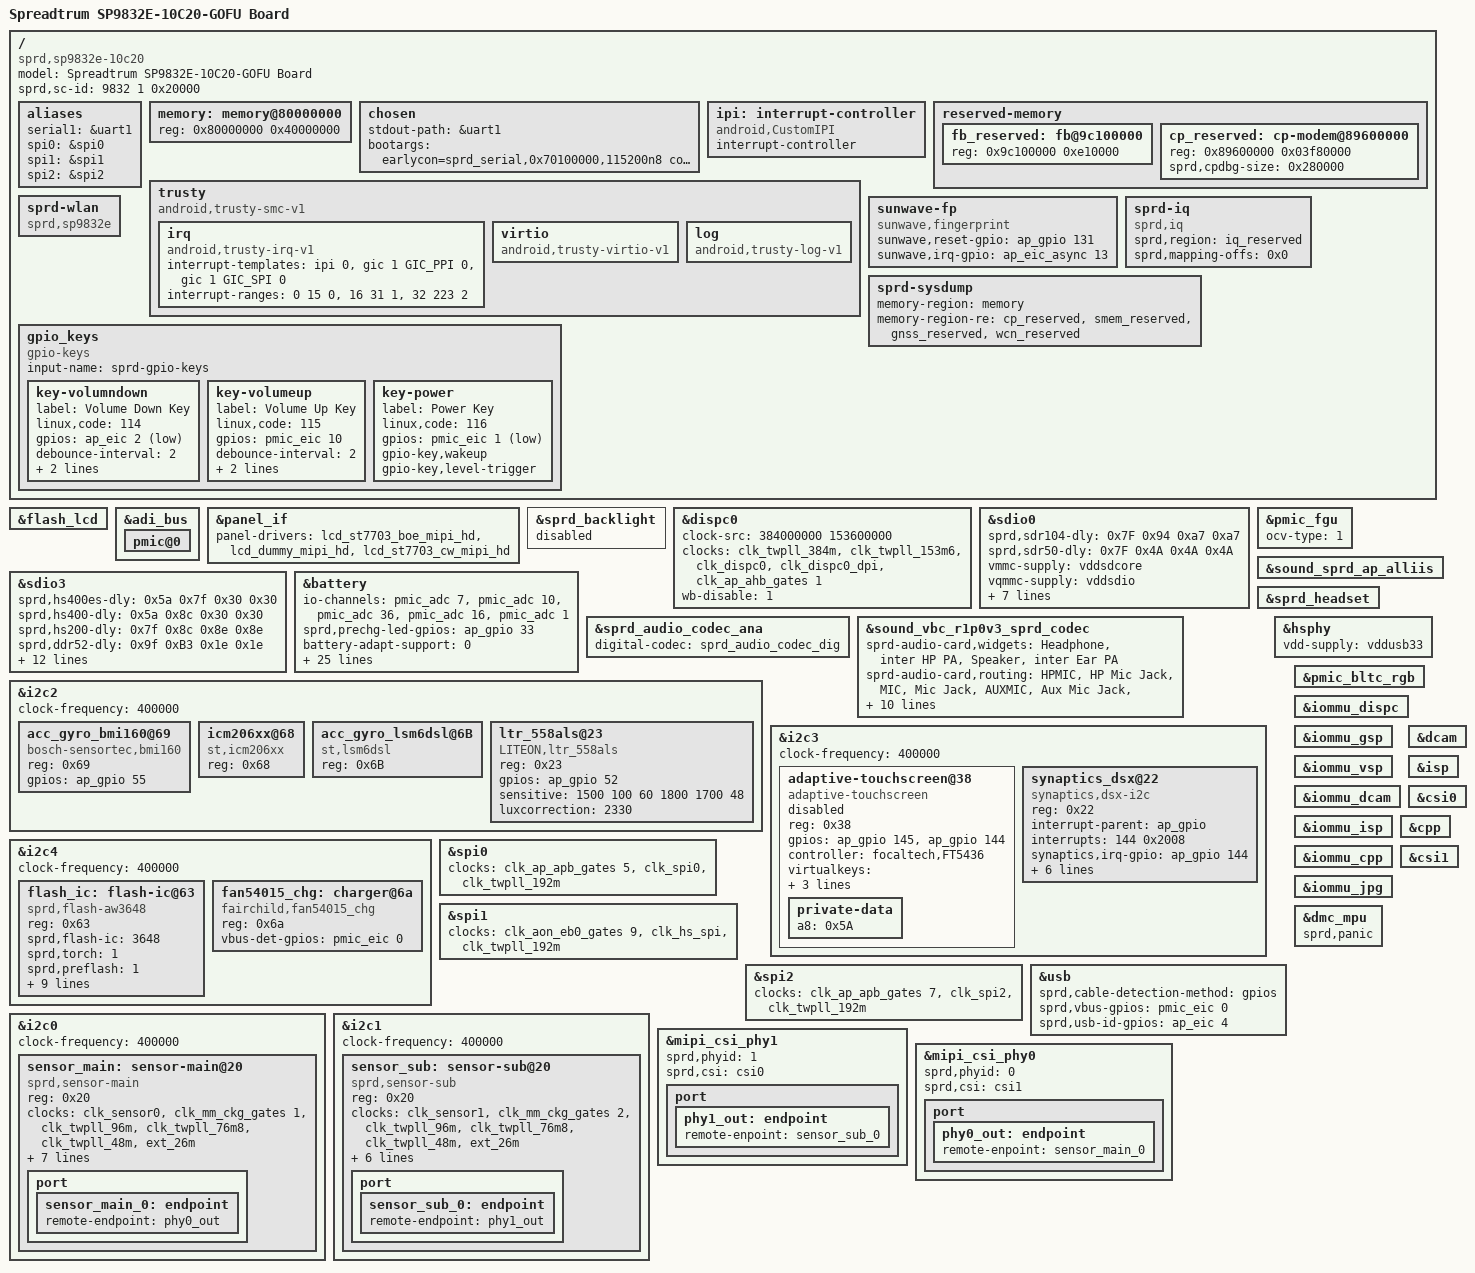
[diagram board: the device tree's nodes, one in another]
/*
 * Spreadtrum SP9832E 1H10 GO FULL board DTS file
 *
 * Copyright (C) 2016-2017, Spreadtrum Communications Inc.
 *
 * This file is licensed under a dual GPLv2 or X11 license.
 */
/dts-v1/;

#include "sc9832e.dtsi"
#include "sp9832e-common.dtsi"
#include "lcd/lcd_st7703_mipi_hd.dtsi"
#include "lcd/lcd_dummy_mipi.dtsi"
#include "lcd/lcd_st7703_mipi_2hd.dtsi"
/ {
	model = "Spreadtrum SP9832E-10C20-GOFU Board";

	compatible = "sprd,sp9832e-10c20", "sprd,sc9832e";

	sprd,sc-id = <9832 1 0x20000>;

	aliases {
		serial1 = &uart1;
		spi0 = &spi0;
		spi1 = &spi1;
		spi2 = &spi2;
	};

	memory: memory@80000000 {
		device_type = "memory";
		reg = <0x80000000 0x40000000>;
	};

	chosen {
		stdout-path = &uart1;
		bootargs = "earlycon=sprd_serial,0x70100000,115200n8 console=ttyS1,115200n8 loglevel=1 init=/init root=/dev/ram0 rw androidboot.hardware=P932F10 vmalloc=360M";
	};

	ipi: interrupt-controller {
		compatible = "android,CustomIPI";
		#interrupt-cells = <1>;
		interrupt-controller;
	};

	reserved-memory {
		/* if changed ,uboot dts also need change */
		fb_reserved: fb@9c100000{
			reg = <0x9c100000 0xe10000>;
		};
		/delete-node/ android_go@a1300000;

		/* cp_reserved = cp region + debug region */
		/* debug region: not reserved in normal mode, it */
		/* will be proccessed in u-boot */
		cp_reserved: cp-modem@89600000 {
			reg = <0x89600000 0x03f80000>;
			/* This prop specifies the size of debug region */
			/* in the cp tail */
			sprd,cpdbg-size = <0x280000>;
		};
	};

	trusty {
		compatible = "android,trusty-smc-v1";

		irq {
			compatible = "android,trusty-irq-v1";
			interrupt-templates = <&ipi 0>,
						<&gic 1 GIC_PPI 0>,
						<&gic 1 GIC_SPI 0>;
			interrupt-ranges = < 0  15 0>,
						<16  31 1>,
						<32 223 2>;
		};

		virtio {
			compatible = "android,trusty-virtio-v1";
		};

		log {
			compatible = "android,trusty-log-v1";
		};
	};

	sunwave-fp {
		compatible = "sunwave,fingerprint";
		sunwave,reset-gpio = <&ap_gpio 131 0 >;
		sunwave,irq-gpio = <&ap_eic_async 13 0 >;
	};

	sprd-iq {
		compatible = "sprd,iq";
		sprd,region = <&iq_reserved>;
		sprd,mapping-offs = <0x0>;
	};

	sprd-sysdump {
		memory-region = <&memory>;
		memory-region-re = <&cp_reserved>, <&smem_reserved>,
				<&gnss_reserved>, <&wcn_reserved>;
	};

	sprd-wlan {
		 compatible = "sprd,sp9832e";
	};

	gpio_keys {
		compatible = "gpio-keys";
		input-name = "sprd-gpio-keys";
		status = "ok";

		key-volumndown {
			label = "Volume Down Key";
			linux,code = <114>;
			gpios = <&ap_eic 2 1>;
			debounce-interval = <2>;
			gpio-key,wakeup;
			gpio-key,level-trigger;
		};

		key-volumeup {
			label = "Volume Up Key";
			linux,code = <115>;
			gpios = <&pmic_eic 10 0>;
			debounce-interval = <2>;
			gpio-key,wakeup;
			gpio-key,level-trigger;
		};

		key-power {
			label = "Power Key";
			linux,code = <116>;
			gpios = <&pmic_eic 1 1>;
			gpio-key,wakeup;
			gpio-key,level-trigger;
		};
	};
};

&flash_lcd {
	status = "okay";
};

&adi_bus {
	pmic@0 {
		/delete-node/ flash@2a8;
	};
};

&panel_if {
	panel-drivers = <
			&lcd_st7703_boe_mipi_hd
			&lcd_dummy_mipi_hd
			&lcd_st7703_cw_mipi_hd
		>;
};

&sprd_backlight {
        status = "disabled";
};

&dispc0 {

        clock-src = <384000000 153600000>;
        clock-names =   "clk_dispc_core_parent",
                        "clk_dispc_dpi_parent",
                        "clk_dispc_core",
                        "clk_dispc_dpi",
                        "clk_dispc_ahb_eb";

        clocks = <&clk_twpll_384m>,
                <&clk_twpll_153m6>,
                <&clk_dispc0>,
                <&clk_dispc0_dpi>,
                <&clk_ap_ahb_gates 1>;

};

&sdio0 {
	sprd,sdr104-dly = <0x7F 0x94 0xa7 0xa7>;
	sprd,sdr50-dly = <0x7F 0x4A 0x4A 0x4A>;
	vmmc-supply = <&vddsdcore>;
	vqmmc-supply = <&vddsdio>;
	voltage-ranges = <3000 3000>;
	bus-width = <4>;
	cd-gpios = <&ap_gpio 78 1>;
	sd-uhs-sdr50;
	sprd,name = "sdio_sd";
	no-sdio;
	no-mmc;
	status = "okay";
};

&sdio3 {
	sprd,hs400es-dly = <0x5A 0x7F 0x30 0x30>;
	sprd,hs400-dly = <0x5A 0x8C 0x30 0x30>;
	sprd,hs200-dly = <0x7F 0x8C 0x8E 0x8E>;
	sprd,ddr52-dly = <0x9F 0xB3 0x1E 0x1E>;
	vmmc-supply = <&vddemmccore>;
	voltage-ranges = <3000 3000>;
	bus-width = <8>;
	non-removable;
	cap-mmc-hw-reset;
	mmc-hs400-enhanced-strobe;
	mmc-hs400-1_8v;
	mmc-hs200-1_8v;
	mmc-ddr-1_8v;
	sprd,name = "sdio_emmc";
	no-sdio;
	no-sd;
	status = "okay";
};

&sdio3 {
	sprd,hs400es-dly = <0x5a 0x7f 0x30 0x30>;
	sprd,hs400-dly = <0x5a 0x8c 0x30 0x30>;
	sprd,hs200-dly = <0x7f 0x8c 0x8e 0x8e>;
	sprd,ddr52-dly = <0x9f 0xB3 0x1e 0x1e>;
	vmmc-supply = <&vddemmccore>;
	voltage-ranges = <3000 3000>;
	bus-width = <8>;
	non-removable;
	cap-mmc-hw-reset;
	sprd,name = "sdio_emmc";
	no-sdio;
	no-sd;
	status = "okay";
};

&battery {
	io-channels = <&pmic_adc 7>,<&pmic_adc 10>,
			<&pmic_adc 36>,<&pmic_adc 16>,<&pmic_adc 1>;
	io-channel-names = "adc_temp","adc_vbat",
			"adc_vchg","adc_isense","adc_id";
	sprd,prechg-led-gpios = <&ap_gpio 33 0>;
	battery-adapt-support = <0>;
	battery-adapt-fun = <0>;
	adp-cdp-cur = <1000>;
	adp-dcp-cur = <1000>;
	adp-sdp-cur = <500>;
	adp-unknown-cur = <500>;
	chg-end-vol = <4350>;
	chg-end-vol-check = <4330>;
	chg-bat-safety-vol = <4430>;
	rechg-vol = <4270>;
	chg-end-vol-z = <4100>;
	chg-end-cur-z = <80>;
	rechg-vol-z = <4020>;
	rsense-real = <200>;
	rint = <197>;
	cnom = <2645>;
	chg-polling-time = <10>;
	jeita-temp-tab = <1000 1100 1150 1450 1580>;
	jeita-temp-recovery-tab = <1030 1130 1180 1420 1550>;
	jeita-cur-tab = <0 780 780 1000 1000 0>;
	jeita-cccv-tab = <4350 4350 4350 4350 4100 4100>;
	ocv-tab-vol = <4324 4256 4199 4146 4094 4055 3986
			3960 3922 3874 3839 3817 3800 3786
			3775 3762 3744 3721 3691 3678 3400>;
	ocv-tab-cap = <100  95   90   85   80   75   70
			65   60   55   50   45   40   35
			30   25   20   15   10   5   0>;
};

&pmic_fgu {
	ocv-type = <1>;
};

&sprd_audio_codec_ana {
	status = "okay";
	digital-codec = <&sprd_audio_codec_dig>;
};

&sound_vbc_r1p0v3_sprd_codec {
	status = "okay";
	sprd-audio-card,widgets =
		"Headphone", "inter HP PA",
                "Speaker", "inter Ear PA";
	sprd-audio-card,routing =
		"HPMIC", "HP Mic Jack",
		"MIC", "Mic Jack",
		"AUXMIC", "Aux Mic Jack",
		"inter HP PA", "HP PA",
		"Ext Spk", "Spk PA",
                "inter Ear PA", "EAR",
		"DMIC", "DMic Jack",
		"DMIC1", "DMic1 Jack",

		/* For vbc loopback */
		"Aud input", "AD Clk",
		"Aud input1", "AD Clk",
		"Aud input", "Digital ADCL Switch",
		"Aud input", "Digital ADCR Switch",
		"Aud input1", "Digital ADC1L Switch",
		"Aud input1", "Digital ADC1R Switch";
	sprd,spk-ext-pa-info = <0 0 2 0>;
	sprd,spk-ext-pa-gpio = <&ap_gpio 63 0>;
	sprd,spk-ext-pa-names = "ext_spk_r";
};

&sound_sprd_ap_alliis {
	status = "okay";
};

&sprd_headset {
	status = "okay";
};

&i2c2 {
	status = "okay";
	clock-frequency = <400000>;

	acc_gyro_bmi160@69{
		compatible = "bosch-sensortec,bmi160";
		reg = <0x69>;
		gpios = <&ap_gpio 55 0>;
	};
	icm206xx@68{
		compatible = "st,icm206xx";
		reg = <0x68>;
		//st,drdy-int-pin = <1>;
	};
	acc_gyro_lsm6dsl@6B{
		compatible = "st,lsm6dsl";
		reg = <0x6B>;
	};
	ltr_558als@23{
		compatible = "LITEON,ltr_558als";
		reg = <0x23>;
		gpios = <&ap_gpio 52 0>;
		sensitive = <1500 100 60
					1800 1700 48>;
		luxcorrection = <2330>;
	};
};

&i2c3 {
        status = "okay";
        clock-frequency = <400000>;
	adaptive-touchscreen@38 {
		compatible = "adaptive-touchscreen";
		reg = <0x38>;
		status = "disabled";
		gpios = <&ap_gpio 145 0
			&ap_gpio 144 0>;
		controller = "focaltech,FT5436";
		virtualkeys = <580 60 1320 60 45
				172 360 1320 60 45
				158 600 1320 60 45>;
		surface-width = <720>;
		surface-height = <1280>;
		private-data {
		a8 = /bits/ 8 <0x5A>;
		};
	};
	synaptics_dsx@22 {
		compatible = "synaptics,dsx-i2c";
		reg = <0x22>;
		interrupt-parent = <&ap_gpio>;
		interrupts = <144 0x2008>;
		synaptics,irq-gpio = <&ap_gpio 144 0x2008>; /* IRQF_ONESHOT | IRQF_TRIGGER_LOW */
		synaptics,reset-gpio = <&ap_gpio 145 0>;
		synaptics,irq-on-state = <0>;
		synaptics,power-delay-ms = <200>;
		synaptics,reset-delay-ms = <200>;
		synaptics,reset-on-state = <0>;
		synaptics,reset-active-ms = <20>;
	};
};

&i2c4 {
	status = "okay";
	clock-frequency = <400000>;
	flash_ic: flash-ic@63 {
		compatible = "sprd,flash-aw3648";
		reg = <0x63>;
		sprd,flash-ic = <3648>;
		sprd,torch = <1>;
		sprd,preflash = <1>;
		sprd,highlight = <1>;
		sprd,torch-level = <10>;
		sprd,preflash-level = <15>;
		sprd,highlight-level = <15>;
		sprd,lvfm-enable = <1>;
		flash-torch-en-gpios = <&ap_gpio 76 0>;
		flash-chip-en-gpios = <&ap_gpio 89 0>;
		flash-en-gpios = <&ap_gpio 76 0>;
		flash-sync-gpios = <&ap_gpio 76 0>;
	};

	fan54015_chg: charger@6a {
		compatible = "fairchild,fan54015_chg";
		reg = <0x6a>;
		vbus-det-gpios = <&pmic_eic 0 0>;
	};
};

&spi0 {
	/*used for fingerprint sensor*/
	status = "okay";
	clocks = <&clk_ap_apb_gates 5>, <&clk_spi0>, <&clk_twpll_192m>;
};

&spi1 {
	clocks = <&clk_aon_eb0_gates 9>, <&clk_hs_spi>, <&clk_twpll_192m>;
};

&spi2 {
	clocks = <&clk_ap_apb_gates 7>, <&clk_spi2>, <&clk_twpll_192m>;
};

&hsphy {
	vdd-supply = <&vddusb33>;
};

&usb {
	sprd,cable-detection-method = "gpios";
	sprd,vbus-gpios = <&pmic_eic 0 0>;
	sprd,usb-id-gpios = <&ap_eic 4 0>;
};

&pmic_bltc_rgb {
	status = "okay";
};

&dispc0 {
	wb-disable = <1>;
};

&iommu_dispc {
	status = "okay";
};

&iommu_gsp {
	status = "okay";
};

&iommu_vsp {
	status = "okay";
};

&iommu_dcam {
	status = "okay";
};

&iommu_isp {
	status = "okay";
};

&iommu_cpp {
	status = "okay";
};

&iommu_jpg {
	status = "okay";
};

&dcam {
	status = "okay";
};

&isp {
	status = "okay";
};

&csi0 {
	status = "okay";
};

&cpp {
	status = "okay";
};

&csi1 {
	status = "okay";
};

&i2c0 {
	status = "okay";
	clock-frequency = <400000>;

	sensor_main: sensor-main@20 {
		compatible = "sprd,sensor-main";
		reg = <0x20>;
		clock-names = "clk_src","sensor_eb",
			"clk_96m","clk_76m8",
			"clk_48m","clk_26m";
		clocks = <&clk_sensor0>, <&clk_mm_ckg_gates 1>,
			<&clk_twpll_96m>,<&clk_twpll_76m8>,
			<&clk_twpll_48m>,<&ext_26m>;
		vddio-supply = <&vddcamio>;
		avdd-gpios = <&ap_gpio 134 0>;
		vddcamd-supply = <&vddcamd>;
		vddcammot-supply = <&vddcammot>;
		reset-gpios = <&ap_gpio 44 0>;
		power-down-gpios = <&ap_gpio 46 0>;
		host = "dcam1";
		port {
			sensor_main_0: endpoint {
				remote-endpoint = <&phy0_out>;
			};
		};
	};
};

&i2c1 {
	status = "okay";
	clock-frequency = <400000>;

	sensor_sub: sensor-sub@20 {
		compatible = "sprd,sensor-sub";
		reg = <0x20>;
		clock-names = "clk_src","sensor_eb",
				"clk_96m","clk_76m8",
				"clk_48m","clk_26m";
		clocks = <&clk_sensor1>, <&clk_mm_ckg_gates 2>,
			<&clk_twpll_96m>,<&clk_twpll_76m8>,
			<&clk_twpll_48m>,<&ext_26m>;
		vddio-supply = <&vddcamio>;
		vddcama-supply = <&vddcama>;
		vddcamd-supply = <&vddcamd>;
		reset-gpios = <&ap_gpio 45 0>;
		power-down-gpios = <&ap_gpio 47 0>;
		host = "dcam0";
		port {
			sensor_sub_0: endpoint {
				remote-endpoint = <&phy1_out>;
			};
		};
	};
};

&mipi_csi_phy1 {
	status = "okay";
	sprd,phyid = <1>;
	sprd,csi = <&csi0>;
	port {
	phy1_out: endpoint {
		remote-enpoint = <&sensor_sub_0>;
		};
	};
};

&mipi_csi_phy0 {
	status = "okay";
	sprd,phyid = <0>;
	sprd,csi = <&csi1>;
	port {
		phy0_out: endpoint {
			remote-enpoint = <&sensor_main_0>;
		};
	};
};

&dmc_mpu {
	sprd,panic;
	status = "ok";
};
